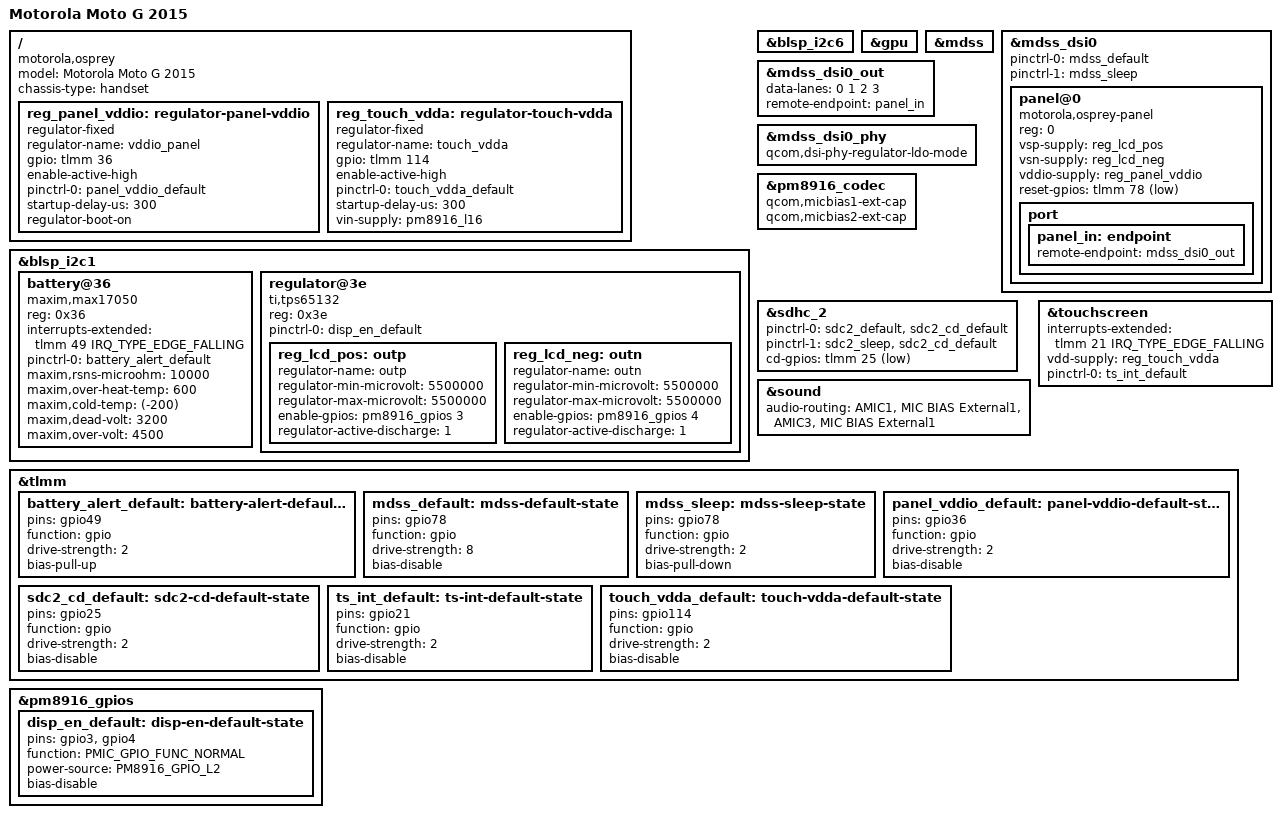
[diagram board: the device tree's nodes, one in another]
// SPDX-License-Identifier: GPL-2.0-only

/dts-v1/;

#include "msm8916-motorola-common.dtsi"
#include <dt-bindings/pinctrl/qcom,pmic-gpio.h>

/ {
	model = "Motorola Moto G 2015";
	compatible = "motorola,osprey", "qcom,msm8916";
	chassis-type = "handset";

	reg_panel_vddio: regulator-panel-vddio {
		compatible = "regulator-fixed";
		regulator-name = "vddio_panel";
		gpio = <&tlmm 36 GPIO_ACTIVE_HIGH>;
		enable-active-high;
		pinctrl-0 = <&panel_vddio_default>;
		pinctrl-names = "default";
		startup-delay-us = <300>;
		regulator-boot-on;
	};

	reg_touch_vdda: regulator-touch-vdda {
		compatible = "regulator-fixed";
		regulator-name = "touch_vdda";
		gpio = <&tlmm 114 GPIO_ACTIVE_HIGH>;
		enable-active-high;
		pinctrl-0 = <&touch_vdda_default>;
		pinctrl-names = "default";
		startup-delay-us = <300>;
		vin-supply = <&pm8916_l16>;
	};
};

&blsp_i2c1 {
	status = "okay";

	battery@36 {
		compatible = "maxim,max17050";
		reg = <0x36>;

		interrupts-extended = <&tlmm 49 IRQ_TYPE_EDGE_FALLING>;

		pinctrl-0 = <&battery_alert_default>;
		pinctrl-names = "default";

		maxim,rsns-microohm = <10000>;
		maxim,over-heat-temp = <600>;
		maxim,cold-temp = <(-200)>;
		maxim,dead-volt = <3200>;
		maxim,over-volt = <4500>;

	};

	regulator@3e {
		compatible = "ti,tps65132";
		reg = <0x3e>;

		pinctrl-0 = <&disp_en_default>;
		pinctrl-names = "default";

		reg_lcd_pos: outp {
			regulator-name = "outp";
			regulator-min-microvolt = <5500000>;
			regulator-max-microvolt = <5500000>;
			enable-gpios = <&pm8916_gpios 3 GPIO_ACTIVE_HIGH>;
			regulator-active-discharge = <1>;
		};

		reg_lcd_neg: outn {
			regulator-name = "outn";
			regulator-min-microvolt = <5500000>;
			regulator-max-microvolt = <5500000>;
			enable-gpios = <&pm8916_gpios 4 GPIO_ACTIVE_HIGH>;
			regulator-active-discharge = <1>;
		};
	};
};

&blsp_i2c6 {
	/* magnetometer@c */
};

&gpu {
	status = "okay";
};

&mdss {
	status = "okay";
};

&mdss_dsi0 {
	pinctrl-0 = <&mdss_default>;
	pinctrl-1 = <&mdss_sleep>;
	pinctrl-names = "default", "sleep";

	panel@0 {
		compatible = "motorola,osprey-panel";
		reg = <0>;

		vsp-supply = <&reg_lcd_pos>;
		vsn-supply = <&reg_lcd_neg>;
		vddio-supply = <&reg_panel_vddio>;

		reset-gpios = <&tlmm 78 GPIO_ACTIVE_LOW>;

		port {
			panel_in: endpoint {
				remote-endpoint = <&mdss_dsi0_out>;
			};
		};
	};
};

&mdss_dsi0_out {
	data-lanes = <0 1 2 3>;
	remote-endpoint = <&panel_in>;
};

&mdss_dsi0_phy {
	qcom,dsi-phy-regulator-ldo-mode;
};

&pm8916_codec {
	qcom,micbias1-ext-cap;
	qcom,micbias2-ext-cap;
};

&sdhc_2 {
	pinctrl-0 = <&sdc2_default &sdc2_cd_default>;
	pinctrl-1 = <&sdc2_sleep &sdc2_cd_default>;
	pinctrl-names = "default", "sleep";

	cd-gpios = <&tlmm 25 GPIO_ACTIVE_LOW>;
};

&sound {
	audio-routing =
		"AMIC1", "MIC BIAS External1",
		"AMIC3", "MIC BIAS External1";
};

&touchscreen {
	interrupts-extended = <&tlmm 21 IRQ_TYPE_EDGE_FALLING>;

	vdd-supply = <&reg_touch_vdda>;

	pinctrl-0 = <&ts_int_default>;
	pinctrl-names = "default";
};

&tlmm {
	battery_alert_default: battery-alert-default-state {
		pins = "gpio49";
		function = "gpio";
		drive-strength = <2>;
		bias-pull-up;
	};

	mdss_default: mdss-default-state {
		pins = "gpio78";
		function = "gpio";
		drive-strength = <8>;
		bias-disable;
	};

	mdss_sleep: mdss-sleep-state {
		pins = "gpio78";
		function = "gpio";
		drive-strength = <2>;
		bias-pull-down;
	};

	panel_vddio_default: panel-vddio-default-state {
		pins = "gpio36";
		function = "gpio";
		drive-strength = <2>;
		bias-disable;
	};

	sdc2_cd_default: sdc2-cd-default-state {
		pins = "gpio25";
		function = "gpio";
		drive-strength = <2>;
		bias-disable;
	};

	ts_int_default: ts-int-default-state {
		pins = "gpio21";
		function = "gpio";
		drive-strength = <2>;
		bias-disable;
	};

	touch_vdda_default: touch-vdda-default-state {
		pins = "gpio114";
		function = "gpio";
		drive-strength = <2>;
		bias-disable;
	};
};

&pm8916_gpios {
	disp_en_default: disp-en-default-state {
		pins = "gpio3", "gpio4";
		function = PMIC_GPIO_FUNC_NORMAL;
		power-source = <PM8916_GPIO_L2>;
		bias-disable;
	};
};
